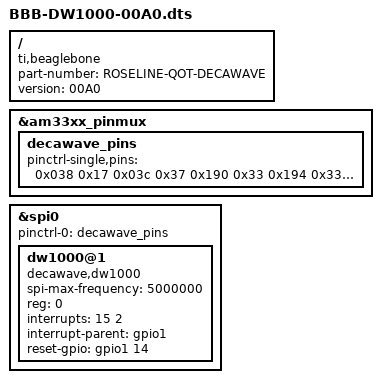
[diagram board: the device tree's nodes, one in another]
/dts-v1/;
/plugin/;
 
/ {
    /* what boards are we compatible with */
    compatible = "ti,beaglebone", "ti,beaglebone-black";
 
    /* identification */
    part-number = "ROSELINE-QOT-DECAWAVE";
 
    /* special version ignores EEPROM */
    version = "00A0";
 
    /* pin multiplexing */
    fragment@0 {
        target = <&am33xx_pinmux>;
        __overlay__ {
            decawave_pins: decawave_pins {
                pinctrl-single,pins = <
                    0x038 0x17      /* RESET P8.16 O_PULLUP | MODE7-GPIO1[14] */
                    0x03c 0x37      /* IRQ P8.15 I_PULLUP | MODE7-GPIO1[15] */
                    0x190 0x33      /* P9.31 CLK INPUT_PULLUP | MODE3 */
                    0x194 0x33      /* P9.29 MISO INPUT_PULLUP | MODE3 */
                    0x198 0x13      /* P9.30 MOSI OUTPUT_PULLUP | MODE3 */
                    0x19c 0x13      /* P9.28 CS0  OUTPUT_PULLUP | MODE3 */
                 >;
            };
        };
    };
 
    /* define the basic driverset for pinmuxing timers and initializing the qot kernel */
    fragment@1 {
        target = <&spi0>;
        __overlay__ {
            #address-cells = <1>;
            #size-cells = <0>;
            status = "okay";
            pinctrl-names = "default";
            pinctrl-0 = <&decawave_pins>;
            dw1000@1 {
                spi-max-frequency = <5000000>;
                reg = <0>;
                compatible = "decawave,dw1000";
                interrupts = <15 2>;
                interrupt-parent = <&gpio1>;
                reset-gpio = <&gpio1 14 0>;
            };
        };
    };
};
